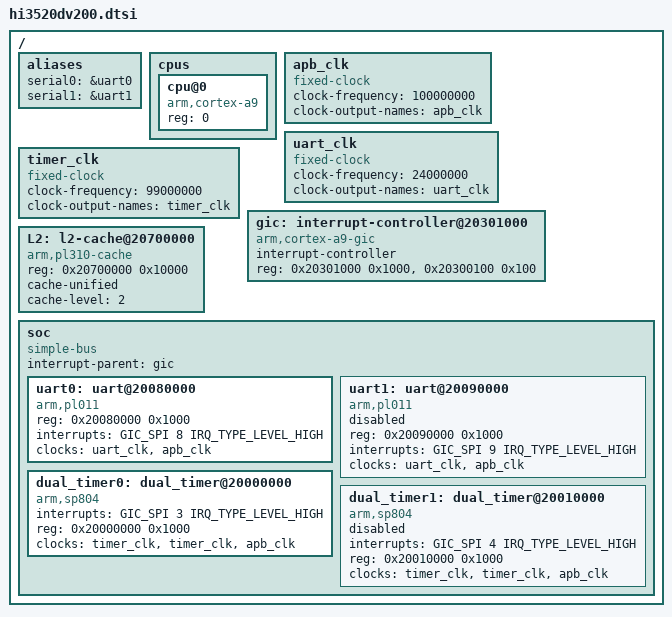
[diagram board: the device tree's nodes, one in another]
/*
 * DTS for HiSilicon Hi3520DV200 (Cortex-A9 single, V1-era DVR/NVR).
 *
 * Phase 4.7 backport: ports the vendor 3.0 mach-hi3520d to Linux 4.9.37
 * DT-based boot.  Single-CPU (Hi3520DV200 is single-A9), no SMP.
 *
 * Memory map from vendor `arch/arm/mach-hi3520d/include/mach/platform.h`:
 *   ARM_INTNL_BASE 0x20300000 (A9 mpcore: SCU + GIC cpu @+0x100 + dist @+0x1000)
 *   PL310 L2 cache: 0x20700000
 *   CRG:    0x20030000
 *   SCTL:   0x20050000
 *   UART0:  0x20080000  IRQ SPI 8
 *   UART1:  0x20090000  IRQ SPI 9
 *   TIMER0: 0x20000000  IRQ SPI 3 (TIMER01_IRQ in vendor irqs.h)
 *   TIMER1: 0x20010000  IRQ SPI 4 (TIMER23_IRQ)
 *   I2C0:   0x200d0000
 *   RTC:    0x20060000
 *
 * Vendor uses ATAGs MACHINE_START "hi3520d" with MACH_TYPE 8000.  This
 * port replaces it with DT_MACHINE_START via compat "hisilicon,hi3520dv200".
 *
 * No HiSilicon clock controller driver exists for V1-era CRG layout;
 * use fixed-rate clocks for UART and SP804 timer.  Timer rate 99 MHz
 * matches QEMU SoC config (timer_freq = 99000000 = busclk/4 with
 * busclk = 396 MHz from CRG defaults).
 */

#include <dt-bindings/interrupt-controller/arm-gic.h>
#include <dt-bindings/interrupt-controller/irq.h>

/ {
	#address-cells = <1>;
	#size-cells = <1>;

	aliases {
		serial0 = &uart0;
		serial1 = &uart1;
	};

	cpus {
		#address-cells = <1>;
		#size-cells = <0>;

		cpu@0 {
			device_type = "cpu";
			compatible = "arm,cortex-a9";
			reg = <0>;
		};
	};

	apb_clk: apb_clk {
		#clock-cells = <0>;
		compatible = "fixed-clock";
		clock-frequency = <100000000>;
		clock-output-names = "apb_clk";
	};

	uart_clk: uart_clk {
		#clock-cells = <0>;
		compatible = "fixed-clock";
		clock-frequency = <24000000>;
		clock-output-names = "uart_clk";
	};

	timer_clk: timer_clk {
		#clock-cells = <0>;
		compatible = "fixed-clock";
		clock-frequency = <99000000>;
		clock-output-names = "timer_clk";
	};

	gic: interrupt-controller@20301000 {
		compatible = "arm,cortex-a9-gic";
		#interrupt-cells = <3>;
		#address-cells = <0>;
		interrupt-controller;
		reg = <0x20301000 0x1000>, <0x20300100 0x100>;
	};

	L2: l2-cache@20700000 {
		compatible = "arm,pl310-cache";
		reg = <0x20700000 0x10000>;
		cache-unified;
		cache-level = <2>;
	};

	soc {
		#address-cells = <1>;
		#size-cells = <1>;
		compatible = "simple-bus";
		interrupt-parent = <&gic>;
		ranges;

		uart0: uart@20080000 {
			compatible = "arm,pl011", "arm,primecell";
			reg = <0x20080000 0x1000>;
			interrupts = <GIC_SPI 8 IRQ_TYPE_LEVEL_HIGH>;
			clocks = <&uart_clk>, <&apb_clk>;
			clock-names = "uartclk", "apb_pclk";
			status = "okay";
		};

		uart1: uart@20090000 {
			compatible = "arm,pl011", "arm,primecell";
			reg = <0x20090000 0x1000>;
			interrupts = <GIC_SPI 9 IRQ_TYPE_LEVEL_HIGH>;
			clocks = <&uart_clk>, <&apb_clk>;
			clock-names = "uartclk", "apb_pclk";
			status = "disabled";
		};

		dual_timer0: dual_timer@20000000 {
			compatible = "arm,sp804", "arm,primecell";
			interrupts = <GIC_SPI 3 IRQ_TYPE_LEVEL_HIGH>;
			reg = <0x20000000 0x1000>;
			clocks = <&timer_clk>, <&timer_clk>, <&apb_clk>;
			clock-names = "timer0", "timer1", "apb_pclk";
		};

		dual_timer1: dual_timer@20010000 {
			compatible = "arm,sp804", "arm,primecell";
			interrupts = <GIC_SPI 4 IRQ_TYPE_LEVEL_HIGH>;
			reg = <0x20010000 0x1000>;
			clocks = <&timer_clk>, <&timer_clk>, <&apb_clk>;
			clock-names = "timer2", "timer3", "apb_pclk";
			status = "disabled";
		};
	};
};
